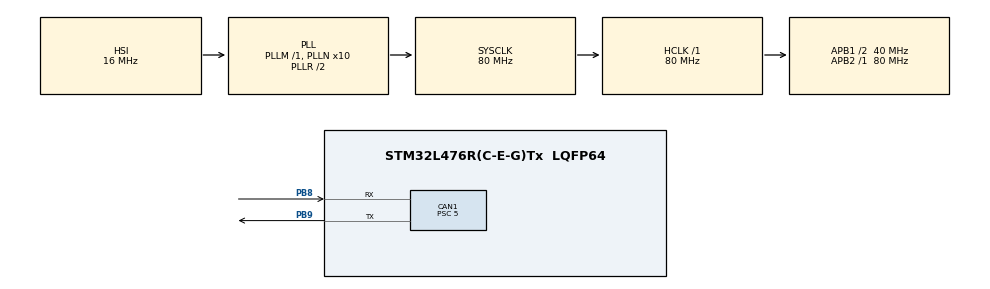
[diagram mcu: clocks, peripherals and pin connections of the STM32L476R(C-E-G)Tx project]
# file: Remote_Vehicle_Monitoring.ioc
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CAN1.BS1=CAN_BS1_13TQ
CAN1.BS2=CAN_BS2_2TQ
CAN1.CalculateTimeQuantum=125.0
CAN1.NART=ENABLE
CAN1.Prescaler=5
Mcu.Family=STM32L4
Mcu.Name=STM32L476R(C-E-G)Tx
Mcu.Package=LQFP64
NVIC.CAN1_RX0_IRQn=true\:0\:0\:false\:false\:true\:true\:true
NVIC.CAN1_TX_IRQn=true\:0\:0\:false\:false\:true\:true\:true
NVIC.PriorityGroup=NVIC_PRIORITYGROUP_4
PA13\ (JTMS-SWDIO).Mode=Serial_Wire
PA13\ (JTMS-SWDIO).Signal=SYS_JTMS-SWDIO
PA14\ (JTCK-SWCLK).Mode=Serial_Wire
PA14\ (JTCK-SWCLK).Signal=SYS_JTCK-SWCLK
PB3\ (JTDO-TRACESWO).Signal=SYS_JTDO-SWO
PB8.Mode=Master
PB8.Signal=CAN1_RX
PB9.Mode=Master
PB9.Signal=CAN1_TX
PC14-OSC32_IN\ (PC14).Mode=LSE-External-Oscillator
PC14-OSC32_IN\ (PC14).Signal=RCC_OSC32_IN
PC15-OSC32_OUT\ (PC15).Mode=LSE-External-Oscillator
PC15-OSC32_OUT\ (PC15).Signal=RCC_OSC32_OUT
ProjectManager.HeapSize=0x200
ProjectManager.StackSize=0x400
ProjectManager.TargetToolchain=STM32CubeIDE
RCC.ADCFreq_Value=64000000
RCC.AHBFreq_Value=80000000
RCC.APB1CLKDivider=RCC_HCLK_DIV2
RCC.APB1Freq_Value=40000000
RCC.APB1TimFreq_Value=80000000
RCC.APB2Freq_Value=80000000
RCC.APB2TimFreq_Value=80000000
RCC.CortexFreq_Value=80000000
RCC.HCLKFreq_Value=80000000
RCC.HSE_VALUE=8000000
RCC.HSI_VALUE=16000000
RCC.MSI_VALUE=4000000
RCC.PLLN=10
RCC.PLLSourceVirtual=RCC_PLLSOURCE_HSI
RCC.PREFETCH_ENABLE=1
RCC.SYSCLKFreq_VALUE=80000000
RCC.SYSCLKSource=RCC_SYSCLKSOURCE_PLLCLK
RCC.USBFreq_Value=64000000
RCC.VCOOutputFreq_Value=160000000
VP_WWDG_VS_WWDG.Mode=WWDG_Activate
WWDG.Counter=127
WWDG.Prescaler=WWDG_PRESCALER_8
WWDG.Window=127
board=NUCLEO-L476RG

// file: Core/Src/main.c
/* USER CODE BEGIN Header */
/**
  ******************************************************************************
  * @file           : main.c
  * @brief          : Main program body
  ******************************************************************************
  * @attention
  *
  * <h2><center>&copy; Copyright (c) 2020 STMicroelectronics.
  * All rights reserved.</center></h2>
  *
  * This software component is licensed by ST under BSD 3-Clause license,
  * the "License"; You may not use this file except in compliance with the
  * License. You may obtain a copy of the License at:
  *                        opensource.org/licenses/BSD-3-Clause
  *
  ******************************************************************************
  */
/* USER CODE END Header */

#include "main.h"
#include "can.h"
#include "wwdg.h"
#include "gpio.h"

void SystemClock_Config(void);

int main(void)
{
	/* USER CODE BEGIN 1 */
	uint8_t TxData[8] = {0x02, 0x01, 0x0C, 0xCC, 0xCC, 0xCC, 0xCC, 0xCC}; // get RPM
	uint32_t TxMailbox;

	/* USER CODE END 1 */

	/* MCU Configuration--------------------------------------------------------*/

	/* Reset of all peripherals, Initializes the Flash interface and the Systick. */
	HAL_Init();

	/* Configure the system clock */
	SystemClock_Config();

	/* Initialize all configured peripherals */
	MX_GPIO_Init();
	MX_CAN1_Init();
	//MX_WWDG_Init();
	/* USER CODE BEGIN 2 */
	MX_CAN1_InitBis();

	/* USER CODE END 2 */

	/* Infinite loop */
	/* USER CODE BEGIN WHILE */
	while (1)
	{
		//MX_WWDG_Refresh();
		/* Start the Transmission process */
		if (HAL_CAN_AddTxMessage(&hcan1, &TxHeader, TxData, &TxMailbox) != HAL_OK)
		{
			/* Transmission request Error */
			Error_Handler();
		}
		HAL_Delay(10);
		/* USER CODE END WHILE */
	}
}

void SystemClock_Config(void)
{
  RCC_OscInitTypeDef RCC_OscInitStruct = {0};
  RCC_ClkInitTypeDef RCC_ClkInitStruct = {0};

  /** Initializes the CPU, AHB and APB busses clocks
  */
  RCC_OscInitStruct.OscillatorType = RCC_OSCILLATORTYPE_HSI;
  RCC_OscInitStruct.HSIState = RCC_HSI_ON;
  RCC_OscInitStruct.HSICalibrationValue = RCC_HSICALIBRATION_DEFAULT;
  RCC_OscInitStruct.PLL.PLLState = RCC_PLL_ON;
  RCC_OscInitStruct.PLL.PLLSource = RCC_PLLSOURCE_HSI;
  RCC_OscInitStruct.PLL.PLLM = 1;
  RCC_OscInitStruct.PLL.PLLN = 10;
  RCC_OscInitStruct.PLL.PLLP = RCC_PLLP_DIV7;
  RCC_OscInitStruct.PLL.PLLQ = RCC_PLLQ_DIV2;
  RCC_OscInitStruct.PLL.PLLR = RCC_PLLR_DIV2;
  if (HAL_RCC_OscConfig(&RCC_OscInitStruct) != HAL_OK)
  {
    Error_Handler();
  }
  /** Initializes the CPU, AHB and APB busses clocks
  */
  RCC_ClkInitStruct.ClockType = RCC_CLOCKTYPE_HCLK|RCC_CLOCKTYPE_SYSCLK
                              |RCC_CLOCKTYPE_PCLK1|RCC_CLOCKTYPE_PCLK2;
  RCC_ClkInitStruct.SYSCLKSource = RCC_SYSCLKSOURCE_PLLCLK;
  RCC_ClkInitStruct.AHBCLKDivider = RCC_SYSCLK_DIV1;
  RCC_ClkInitStruct.APB1CLKDivider = RCC_HCLK_DIV2;
  RCC_ClkInitStruct.APB2CLKDivider = RCC_HCLK_DIV1;

  if (HAL_RCC_ClockConfig(&RCC_ClkInitStruct, FLASH_LATENCY_4) != HAL_OK)
  {
    Error_Handler();
  }
  /** Configure the main internal regulator output voltage
  */
  if (HAL_PWREx_ControlVoltageScaling(PWR_REGULATOR_VOLTAGE_SCALE1) != HAL_OK)
  {
    Error_Handler();
  }
}

/* USER CODE BEGIN 4 */

void HAL_CAN_RxFifo0MsgPendingCallback(CAN_HandleTypeDef *hcan)
{
	/* Get RX message */
	if (HAL_CAN_GetRxMessage(hcan, CAN_RX_FIFO0, &RxHeader, RxData) != HAL_OK)
	{
		/* Reception Error */
		Error_Handler();
	}

	/* Display LEDx */
	if ((RxHeader.StdId == 0x321) && (RxHeader.IDE == CAN_ID_STD) && (RxHeader.DLC == 2))
	{
		/* Do something */
	}
}

/* USER CODE END 4 */

void Error_Handler(void)
{
	while (1)
	{
	}
}

/************************ (C) COPYRIGHT STMicroelectronics *****END OF FILE****/
